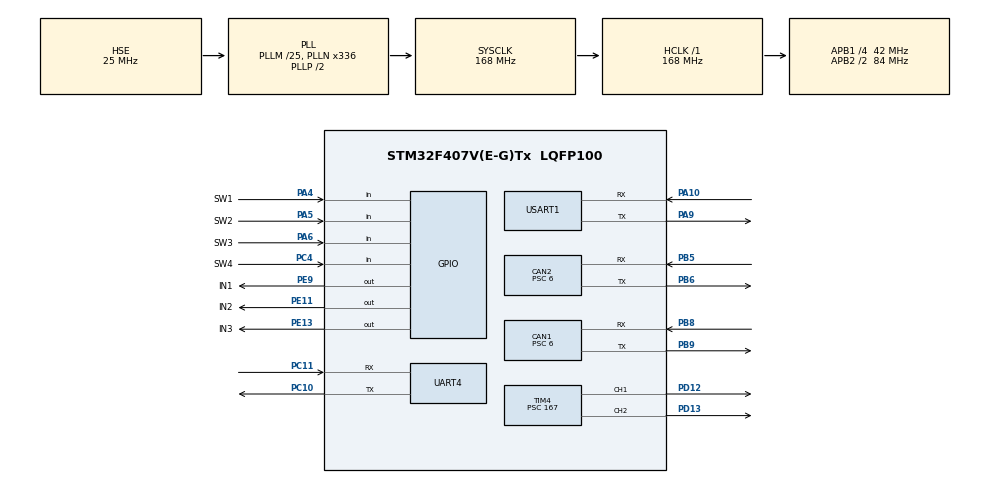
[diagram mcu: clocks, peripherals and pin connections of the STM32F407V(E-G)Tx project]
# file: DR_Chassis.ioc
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CAN1.BS1=CAN_BS1_3TQ
CAN1.BS2=CAN_BS2_3TQ
CAN1.CalculateBaudRate=1000000
CAN1.CalculateTimeBit=999.99
CAN1.CalculateTimeQuantum=142.85714285714286
CAN1.Prescaler=6
CAN2.BS1=CAN_BS1_3TQ
CAN2.BS2=CAN_BS2_3TQ
CAN2.CalculateBaudRate=1000000
CAN2.CalculateTimeBit=999.99
CAN2.CalculateTimeQuantum=142.85714285714286
CAN2.Prescaler=6
Dma.Request0=UART4_RX
Dma.Request1=USART1_RX
Dma.UART4_RX.0.Direction=DMA_PERIPH_TO_MEMORY
Dma.UART4_RX.0.FIFOMode=DMA_FIFOMODE_DISABLE
Dma.UART4_RX.0.Instance=DMA1_Stream2
Dma.UART4_RX.0.MemDataAlignment=DMA_MDATAALIGN_BYTE
Dma.UART4_RX.0.MemInc=DMA_MINC_ENABLE
Dma.UART4_RX.0.Mode=DMA_NORMAL
Dma.UART4_RX.0.PeriphDataAlignment=DMA_PDATAALIGN_BYTE
Dma.UART4_RX.0.PeriphInc=DMA_PINC_DISABLE
Dma.UART4_RX.0.Priority=DMA_PRIORITY_LOW
Dma.USART1_RX.1.Direction=DMA_PERIPH_TO_MEMORY
Dma.USART1_RX.1.FIFOMode=DMA_FIFOMODE_DISABLE
Dma.USART1_RX.1.Instance=DMA2_Stream2
Dma.USART1_RX.1.MemDataAlignment=DMA_MDATAALIGN_BYTE
Dma.USART1_RX.1.MemInc=DMA_MINC_ENABLE
Dma.USART1_RX.1.Mode=DMA_NORMAL
Dma.USART1_RX.1.PeriphDataAlignment=DMA_PDATAALIGN_BYTE
Dma.USART1_RX.1.PeriphInc=DMA_PINC_DISABLE
Dma.USART1_RX.1.Priority=DMA_PRIORITY_LOW
FREERTOS.INCLUDE_vTaskDelayUntil=1
FREERTOS.Tasks01=defaultTask,0,128,StartDefaultTask,Default,NULL,Dynamic,NULL,NULL
Mcu.Family=STM32F4
Mcu.Name=STM32F407V(E-G)Tx
Mcu.Package=LQFP100
NVIC.CAN1_RX0_IRQn=true\:5\:0\:true\:false\:true\:true\:true\:true
NVIC.CAN2_RX1_IRQn=true\:5\:0\:false\:false\:true\:true\:true\:true
NVIC.DMA1_Stream2_IRQn=true\:6\:0\:true\:false\:true\:true\:false\:true
NVIC.DMA2_Stream2_IRQn=true\:6\:0\:true\:false\:true\:true\:false\:true
NVIC.PriorityGroup=NVIC_PRIORITYGROUP_4
NVIC.UART4_IRQn=true\:6\:0\:true\:false\:true\:true\:true\:true
NVIC.USART1_IRQn=true\:6\:0\:true\:false\:true\:true\:true\:true
PA10.Mode=Asynchronous
PA10.Signal=USART1_RX
PA13.Mode=Serial_Wire
PA13.Signal=SYS_JTMS-SWDIO
PA14.Mode=Serial_Wire
PA14.Signal=SYS_JTCK-SWCLK
PA4.GPIO_Label=SW1
PA4.GPIO_PuPd=GPIO_PULLUP
PA4.Signal=GPIO_Input
PA5.GPIO_Label=SW2
PA5.GPIO_PuPd=GPIO_PULLUP
PA5.Signal=GPIO_Input
PA6.GPIO_Label=SW3
PA6.GPIO_PuPd=GPIO_PULLUP
PA6.Signal=GPIO_Input
PA9.Mode=Asynchronous
PA9.Signal=USART1_TX
PB5.Mode=CAN_Activate
PB5.Signal=CAN2_RX
PB6.Mode=CAN_Activate
PB6.Signal=CAN2_TX
PB8.Mode=CAN_Activate
PB8.Signal=CAN1_RX
PB9.Mode=CAN_Activate
PB9.Signal=CAN1_TX
PC10.Mode=Asynchronous
PC10.Signal=UART4_TX
PC11.Mode=Asynchronous
PC11.Signal=UART4_RX
PC4.GPIO_Label=SW4
PC4.GPIO_PuPd=GPIO_PULLUP
PC4.Signal=GPIO_Input
PD12.Signal=S_TIM4_CH1
PD13.Signal=S_TIM4_CH2
PE11.GPIO_Label=IN2
PE11.Signal=GPIO_Output
PE13.GPIO_Label=IN3
PE13.Signal=GPIO_Output
PE9.GPIO_Label=IN1
PE9.Signal=GPIO_Output
PH0-OSC_IN.Mode=HSE-External-Oscillator
PH0-OSC_IN.Signal=RCC_OSC_IN
PH1-OSC_OUT.Mode=HSE-External-Oscillator
PH1-OSC_OUT.Signal=RCC_OSC_OUT
ProjectManager.HeapSize=0x400
ProjectManager.StackSize=0x800
ProjectManager.TargetToolchain=MDK-ARM V5.27
RCC.48MHZClocksFreq_Value=84000000
RCC.AHBFreq_Value=168000000
RCC.APB1CLKDivider=RCC_HCLK_DIV4
RCC.APB1Freq_Value=42000000
RCC.APB1TimFreq_Value=84000000
RCC.APB2CLKDivider=RCC_HCLK_DIV2
RCC.APB2Freq_Value=84000000
RCC.APB2TimFreq_Value=168000000
RCC.CortexFreq_Value=168000000
RCC.HCLKFreq_Value=168000000
RCC.HSE_VALUE=25000000
RCC.HSI_VALUE=16000000
RCC.LSE_VALUE=32768
RCC.PLLM=25
RCC.PLLN=336
RCC.PLLSourceVirtual=RCC_PLLSOURCE_HSE
RCC.SYSCLKFreq_VALUE=168000000
RCC.SYSCLKSource=RCC_SYSCLKSOURCE_PLLCLK
RCC.VCOOutputFreq_Value=336000000
SH.S_TIM4_CH1.0=TIM4_CH1,PWM Generation1 CH1
SH.S_TIM4_CH2.0=TIM4_CH2,PWM Generation2 CH2
TIM2.Period=0xFFFFFFFF
TIM2.Prescaler=839
TIM4.Channel-PWM\ Generation1\ CH1=TIM_CHANNEL_1
TIM4.Channel-PWM\ Generation2\ CH2=TIM_CHANNEL_2
TIM4.Period=9999
TIM4.Prescaler=167
UART4.VirtualMode=Asynchronous
USART1.VirtualMode=VM_ASYNC
VP_FREERTOS_VS_CMSIS_V1.Mode=CMSIS_V1
VP_TIM2_VS_ClockSourceINT.Mode=Internal
board=custom

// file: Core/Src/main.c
/* USER CODE BEGIN Header */
/**
  ******************************************************************************
  * @file           : main.c
  * @brief          : Main program body
  ******************************************************************************
  * @attention
  *
  * <h2><center>&copy; Copyright (c) 2021 STMicroelectronics.
  * All rights reserved.</center></h2>
  *
  * This software component is licensed by ST under Ultimate Liberty license
  * SLA0044, the "License"; You may not use this file except in compliance with
  * the License. You may obtain a copy of the License at:
  *                             www.st.com/SLA0044
  *
  ******************************************************************************
  */
/* USER CODE END Header */
#include "main.h"
#include "cmsis_os.h"
#include "can.h"
#include "dma.h"
#include "tim.h"
#include "usart.h"
#include "gpio.h"

/* USER CODE BEGIN Includes */
#include "RoboModule_DRV.h"
#include "FreeRTOS_Task.h"
/* USER CODE END Includes */

void SystemClock_Config(void);
void MX_FREERTOS_Init(void);

int main(void)
{

  /* MCU Configuration--------------------------------------------------------*/

  /* Reset of all peripherals, Initializes the Flash interface and the Systick. */
  HAL_Init();

  /* Configure the system clock */
  SystemClock_Config();

  /* Initialize all configured peripherals */
  MX_GPIO_Init();
  MX_DMA_Init();
  MX_CAN1_Init();
  MX_UART4_Init();
  MX_USART1_UART_Init();
  MX_TIM4_Init();
  MX_CAN2_Init();
  MX_TIM2_Init();

  /* Call init function for freertos objects (in freertos.c) */
  MX_FREERTOS_Init();
  /* Start scheduler */
  osKernelStart();

  /* We should never get here as control is now taken by the scheduler */
  /* Infinite loop */
  while (1)
  {

  }
}

void SystemClock_Config(void)
{
  RCC_OscInitTypeDef RCC_OscInitStruct = {0};
  RCC_ClkInitTypeDef RCC_ClkInitStruct = {0};

  /** Configure the main internal regulator output voltage
  */
  __HAL_RCC_PWR_CLK_ENABLE();
  __HAL_PWR_VOLTAGESCALING_CONFIG(PWR_REGULATOR_VOLTAGE_SCALE1);
  /** Initializes the RCC Oscillators according to the specified parameters
  * in the RCC_OscInitTypeDef structure.
  */
  RCC_OscInitStruct.OscillatorType = RCC_OSCILLATORTYPE_HSE;
  RCC_OscInitStruct.HSEState = RCC_HSE_ON;
  RCC_OscInitStruct.PLL.PLLState = RCC_PLL_ON;
  RCC_OscInitStruct.PLL.PLLSource = RCC_PLLSOURCE_HSE;
  RCC_OscInitStruct.PLL.PLLM = 25;
  RCC_OscInitStruct.PLL.PLLN = 336;
  RCC_OscInitStruct.PLL.PLLP = RCC_PLLP_DIV2;
  RCC_OscInitStruct.PLL.PLLQ = 4;
  if (HAL_RCC_OscConfig(&RCC_OscInitStruct) != HAL_OK)
  {
    Error_Handler();
  }
  /** Initializes the CPU, AHB and APB buses clocks
  */
  RCC_ClkInitStruct.ClockType = RCC_CLOCKTYPE_HCLK|RCC_CLOCKTYPE_SYSCLK
                              |RCC_CLOCKTYPE_PCLK1|RCC_CLOCKTYPE_PCLK2;
  RCC_ClkInitStruct.SYSCLKSource = RCC_SYSCLKSOURCE_PLLCLK;
  RCC_ClkInitStruct.AHBCLKDivider = RCC_SYSCLK_DIV1;
  RCC_ClkInitStruct.APB1CLKDivider = RCC_HCLK_DIV4;
  RCC_ClkInitStruct.APB2CLKDivider = RCC_HCLK_DIV2;

  if (HAL_RCC_ClockConfig(&RCC_ClkInitStruct, FLASH_LATENCY_5) != HAL_OK)
  {
    Error_Handler();
  }
}

void Error_Handler(void)
{
  __disable_irq();
  while (1)
  {
  }
}

/************************ (C) COPYRIGHT STMicroelectronics *****END OF FILE****/

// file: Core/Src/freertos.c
/* USER CODE BEGIN Header */
/**
  ******************************************************************************
  * File Name          : freertos.c
  * Description        : Code for freertos applications
  ******************************************************************************
  * @attention
  *
  * <h2><center>&copy; Copyright (c) 2021 STMicroelectronics.
  * All rights reserved.</center></h2>
  *
  * This software component is licensed by ST under Ultimate Liberty license
  * SLA0044, the "License"; You may not use this file except in compliance with
  * the License. You may obtain a copy of the License at:
  *                             www.st.com/SLA0044
  *
  ******************************************************************************
  */
/* USER CODE END Header */

#include "FreeRTOS.h"
#include "task.h"
#include "main.h"
#include "cmsis_os.h"

/* USER CODE BEGIN Includes */
#include "FreeRTOS_Task.h"
/* USER CODE END Includes */

osThreadId defaultTaskHandle;

void StartDefaultTask(void const * argument);

void MX_FREERTOS_Init(void); /* (MISRA C 2004 rule 8.1) */

/* GetIdleTaskMemory prototype (linked to static allocation support) */
void vApplicationGetIdleTaskMemory( StaticTask_t **ppxIdleTaskTCBBuffer, StackType_t **ppxIdleTaskStackBuffer, uint32_t *pulIdleTaskStackSize );

/* USER CODE BEGIN GET_IDLE_TASK_MEMORY */
static StaticTask_t xIdleTaskTCBBuffer;
static StackType_t xIdleStack[configMINIMAL_STACK_SIZE];

void vApplicationGetIdleTaskMemory( StaticTask_t **ppxIdleTaskTCBBuffer, StackType_t **ppxIdleTaskStackBuffer, uint32_t *pulIdleTaskStackSize )
{
  *ppxIdleTaskTCBBuffer = &xIdleTaskTCBBuffer;
  *ppxIdleTaskStackBuffer = &xIdleStack[0];
  *pulIdleTaskStackSize = configMINIMAL_STACK_SIZE;
  /* place for user code */
}
/* USER CODE END GET_IDLE_TASK_MEMORY */

void MX_FREERTOS_Init(void) {

  /* Create the thread(s) */
  /* definition and creation of defaultTask */
  osThreadDef(defaultTask, StartDefaultTask, osPriorityNormal, 0, 128);
  defaultTaskHandle = osThreadCreate(osThread(defaultTask), NULL);

}

void StartDefaultTask(void const * argument)
{
  /* USER CODE BEGIN StartDefaultTask */
	vTaskDelay(4000);
    vPortEnterCritical();
    StartTask();
    vPortExitCritical();
    vTaskDelete(NULL);
  /* Infinite loop */
  for(;;)
  {
    osDelay(1);
  }
  /* USER CODE END StartDefaultTask */
}

/************************ (C) COPYRIGHT STMicroelectronics *****END OF FILE****/
